# SA3_SS_RINGACC_0_RINGACC_GCFG_44805000h register map
Vendor: Texas Instruments
Peripheral module from a debugger description file (folder AM275x).
Registers are 32-bit, read-write, reset 0x0 unless marked. A register's access mark holds for its fields unless they carry their own. Offsets are as the file gives them; lines under a group give offsets from that group; [hi:lo] are bit positions; {n}, {i} and the like mark numbered series; 'fields as' and 'values as' point back to an identical list; <NAME> marks a mode.

## ringacc_gcfg
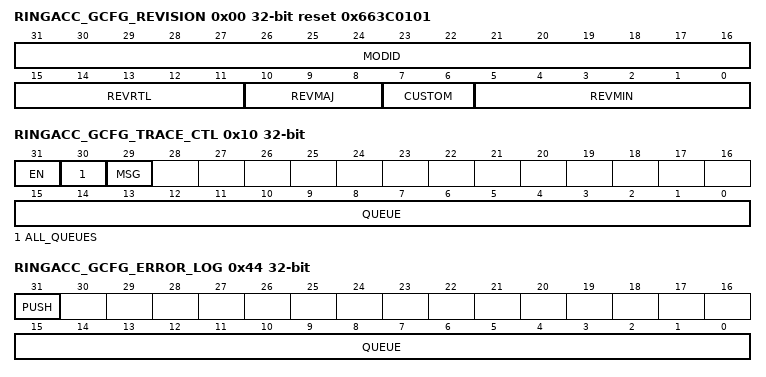
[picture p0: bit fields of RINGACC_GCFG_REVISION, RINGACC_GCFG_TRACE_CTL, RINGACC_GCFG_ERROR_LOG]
0x00 RINGACC_GCFG_REVISION ro reset 0x663C0101 — The Revision Register contains the major and minor revisions for the module.
  [31:16] MODID — Module ID field Reset Source: srst_n
  [15:11] REVRTL — RTL revision. Will vary depending on release. Reset Source: srst_n
  [10:8] REVMAJ — Major revision Reset Source: srst_n
  [7:6] CUSTOM — Custom Reset Source: srst_n
  [5:0] REVMIN — Minor revision Reset Source: srst_n
0x10 RINGACC_GCFG_TRACE_CTL — Trace Control Register
  [31] EN — Trace enable 0 = disable 1 = enable. Reset Source: srst_n
  [30] ALL_QUEUES — Trace everything 0 = only the selected queue 1 = every queue. Reset Source: srst_n
  [29] MSG — Trace message data 0 = include only the operation 1 = include message data. Reset Source: srst_n
  [15:0] QUEUE — Queue number when tracing a single queue. Reset Source: srst_n
0x20 RINGACC_GCFG_OVRFLOW — Overflow Queue Register
  [15:0] QUEUE — Queue to send overflow messages. A value of 0xffff will disable the overflow function. Reset Source: srst_n
0x40 RINGACC_GCFG_ERROR_EVT reset 0xFFFF — The Error Event Register is an Output Event Steering 'OES' register that specifies the event number used to denote detection of a ring memory transaction bus error.
  [15:0] EVT — Event to send when detecting a bus error. Reset Source: srst_n
0x44 RINGACC_GCFG_ERROR_LOG ro — Error Log Register. A read of this register will clear the pending error log event and allow a new error to be captured. It does not clear the contents of this register which are only valid while the error event is pending.
  [31] PUSH — Bus error was caused by a push. 0 = pop. 1 = push. Reset Source: srst_n
  [15:0] QUEUE — Queue that received the bus error. Reset Source: srst_n
